# iostr911fa register map
Registers are 16-bit, access not given, no defined reset value unless marked. A register's access mark holds for its fields unless they carry their own. Addresses are absolute; registers are grouped by the start of their names; [hi:lo] are bit positions; {n}, {i} and the like mark numbered series; 'fields as' and 'values as' point back to an identical list.

## GPIO7
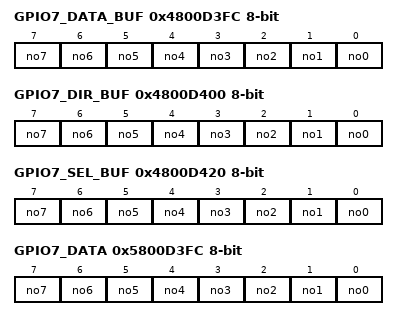
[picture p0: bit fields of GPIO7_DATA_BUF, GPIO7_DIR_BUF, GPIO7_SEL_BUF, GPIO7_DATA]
0x4800D3FC GPIO7_DATA_BUF 8-bit
  [n] no{n} (n=0..7)
0x4800D400 GPIO7_DIR_BUF 8-bit
  [n] no{n} (n=0..7)
0x4800D420 GPIO7_SEL_BUF 8-bit
  [n] no{n} (n=0..7)
0x5800D3FC GPIO7_DATA 8-bit
  [n] no{n} (n=0..7)
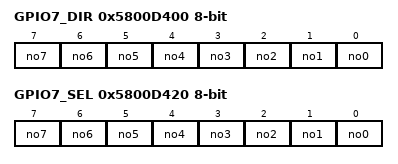
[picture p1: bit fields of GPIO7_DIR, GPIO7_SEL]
0x5800D400 GPIO7_DIR 8-bit
  [n] no{n} (n=0..7)
0x5800D420 GPIO7_SEL 8-bit
  [n] no{n} (n=0..7)

## GPIO8
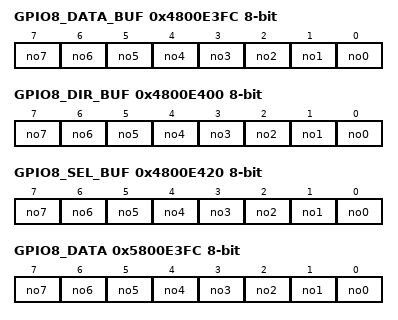
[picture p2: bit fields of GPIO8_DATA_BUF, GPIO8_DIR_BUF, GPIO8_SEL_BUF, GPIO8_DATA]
0x4800E3FC GPIO8_DATA_BUF 8-bit
  [n] no{n} (n=0..7)
0x4800E400 GPIO8_DIR_BUF 8-bit
  [n] no{n} (n=0..7)
0x4800E420 GPIO8_SEL_BUF 8-bit
  [n] no{n} (n=0..7)
0x5800E3FC GPIO8_DATA 8-bit
  [n] no{n} (n=0..7)
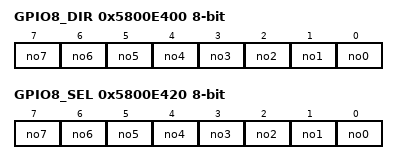
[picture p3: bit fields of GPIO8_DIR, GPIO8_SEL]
0x5800E400 GPIO8_DIR 8-bit
  [n] no{n} (n=0..7)
0x5800E420 GPIO8_SEL 8-bit
  [n] no{n} (n=0..7)

## GPIO9
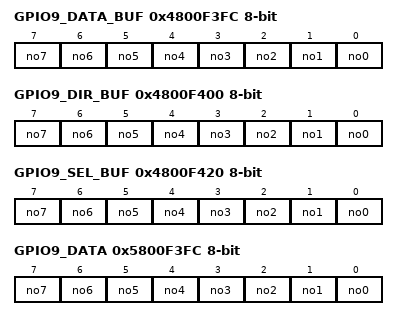
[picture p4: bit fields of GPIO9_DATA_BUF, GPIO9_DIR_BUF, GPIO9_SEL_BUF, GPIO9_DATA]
0x4800F3FC GPIO9_DATA_BUF 8-bit
  [n] no{n} (n=0..7)
0x4800F400 GPIO9_DIR_BUF 8-bit
  [n] no{n} (n=0..7)
0x4800F420 GPIO9_SEL_BUF 8-bit
  [n] no{n} (n=0..7)
0x5800F3FC GPIO9_DATA 8-bit
  [n] no{n} (n=0..7)
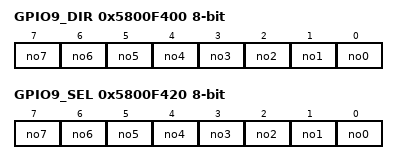
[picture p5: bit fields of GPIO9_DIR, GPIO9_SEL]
0x5800F400 GPIO9_DIR 8-bit
  [n] no{n} (n=0..7)
0x5800F420 GPIO9_SEL 8-bit
  [n] no{n} (n=0..7)

## VIC0
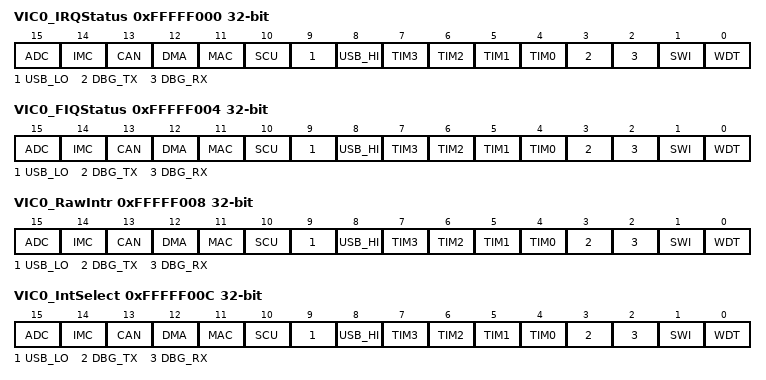
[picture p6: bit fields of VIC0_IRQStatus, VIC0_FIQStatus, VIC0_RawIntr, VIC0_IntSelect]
0xFFFFF000 VIC0_IRQStatus 32-bit
  [15] ADC, [14] IMC, [13] CAN, [12] DMA, [11] MAC, [10] SCU, [9] USB_LO, [8] USB_HI, [n+4] TIM{n} (n=0..3), [3] DBG_TX, [2] DBG_RX, [1] SWI, [0] WDT
0xFFFFF004 VIC0_FIQStatus 32-bit
  fields as VIC0_IRQStatus
0xFFFFF008 VIC0_RawIntr 32-bit
  fields as VIC0_IRQStatus
0xFFFFF00C VIC0_IntSelect 32-bit
  fields as VIC0_IRQStatus
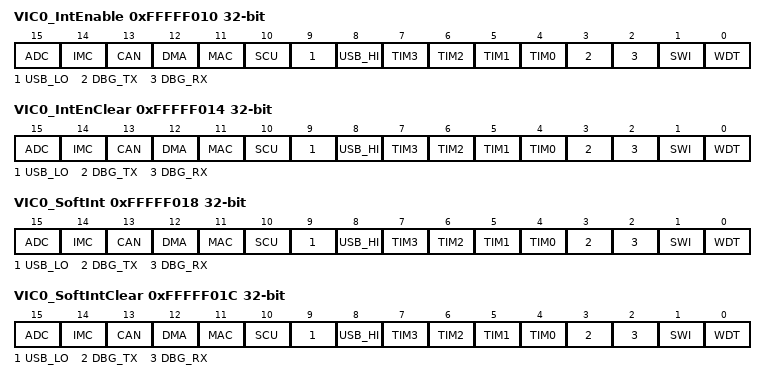
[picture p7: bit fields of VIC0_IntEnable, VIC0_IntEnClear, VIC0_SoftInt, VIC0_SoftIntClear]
0xFFFFF010 VIC0_IntEnable 32-bit
  fields as VIC0_IRQStatus
0xFFFFF014 VIC0_IntEnClear 32-bit
  fields as VIC0_IRQStatus
0xFFFFF018 VIC0_SoftInt 32-bit
  fields as VIC0_IRQStatus
0xFFFFF01C VIC0_SoftIntClear 32-bit
  fields as VIC0_IRQStatus
0xFFFFF020 VIC0_Protection 32-bit
  [0] PROT
0xFFFFF030 VIC0_CurrVectAddr 32-bit
0xFFFFF034 VIC0_DefVectAddr 32-bit
{0xFFFFF100+4i} VIC0_VectAddr{i} 32-bit (i=0..15)
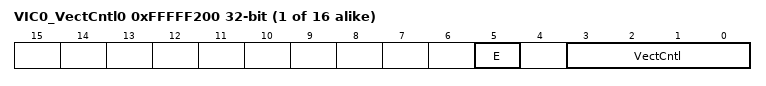
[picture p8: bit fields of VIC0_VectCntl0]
{0xFFFFF200+4i} VIC0_VectCntl{i} 32-bit (i=0..15)
  [5] E, [3:0] VectCntl

## VIC1
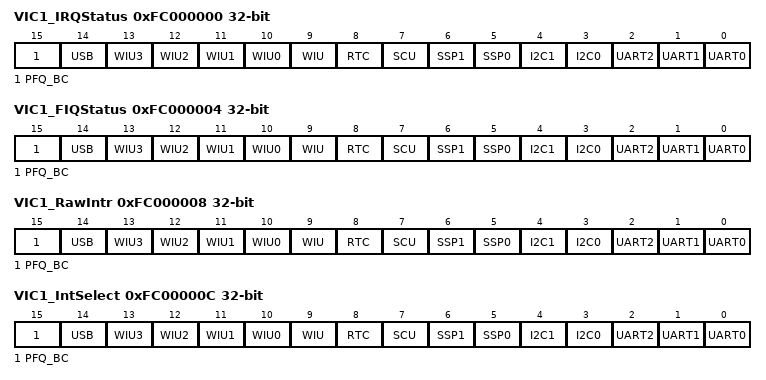
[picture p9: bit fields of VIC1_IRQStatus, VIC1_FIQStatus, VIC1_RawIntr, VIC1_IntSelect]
0xFC000000 VIC1_IRQStatus 32-bit
  [15] PFQ_BC, [14] USB, [n+10] WIU{n} (n=0..3), [9] WIU, [8] RTC, [7] SCU, [6] SSP1, [5] SSP0, [4] I2C1, [3] I2C0, [2] UART2, [1] UART1, [0] UART0
0xFC000004 VIC1_FIQStatus 32-bit
  fields as VIC1_IRQStatus
0xFC000008 VIC1_RawIntr 32-bit
  fields as VIC1_IRQStatus
0xFC00000C VIC1_IntSelect 32-bit
  fields as VIC1_IRQStatus
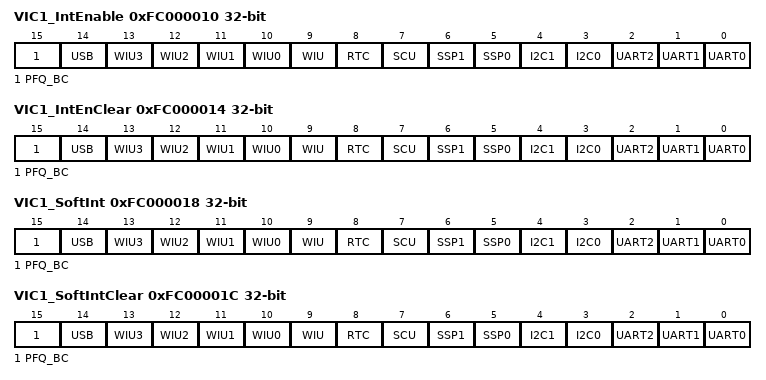
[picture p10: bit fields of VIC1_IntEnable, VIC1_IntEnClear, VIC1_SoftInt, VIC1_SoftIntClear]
0xFC000010 VIC1_IntEnable 32-bit
  fields as VIC1_IRQStatus
0xFC000014 VIC1_IntEnClear 32-bit
  fields as VIC1_IRQStatus
0xFC000018 VIC1_SoftInt 32-bit
  fields as VIC1_IRQStatus
0xFC00001C VIC1_SoftIntClear 32-bit
  fields as VIC1_IRQStatus
0xFC000020 VIC1_Protection 32-bit
  [0] PROT
0xFC000030 VIC1_CurrVectAddr 32-bit
0xFC000034 VIC1_DefVectAddr 32-bit
{0xFC000100+4i} VIC1_VectAddr{i} 32-bit (i=0..15)
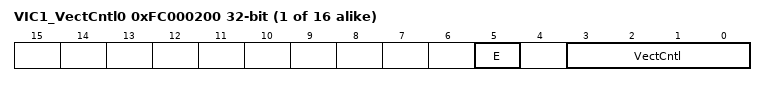
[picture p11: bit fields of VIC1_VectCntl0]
{0xFC000200+4i} VIC1_VectCntl{i} 32-bit (i=0..15)
  [5] E, [3:0] VectCntl

## WIU
0x48001000 WIU_CTRL_BUF 32-bit
  [1] INT_EN
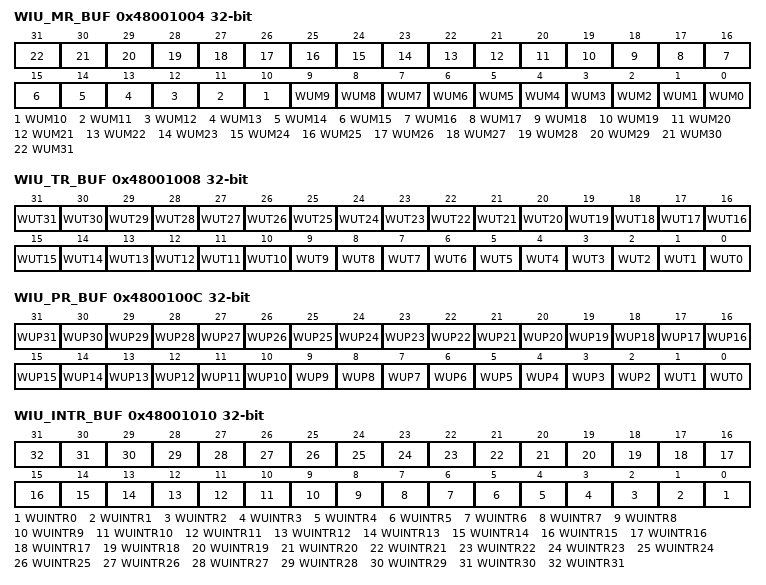
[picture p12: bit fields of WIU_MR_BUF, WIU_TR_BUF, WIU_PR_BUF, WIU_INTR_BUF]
0x48001004 WIU_MR_BUF 32-bit
  [n] WUM{n} (n=0..31)
0x48001008 WIU_TR_BUF 32-bit
  [n] WUT{n} (n=0..31)
0x4800100C WIU_PR_BUF 32-bit
  [n] WUP{n} (n=2..31), [1] WUT1, [0] WUT0
0x48001010 WIU_INTR_BUF 32-bit
  [n] WUINTR{n} (n=0..31)
0x58001000 WIU_CTRL 32-bit
  [1] INT_EN
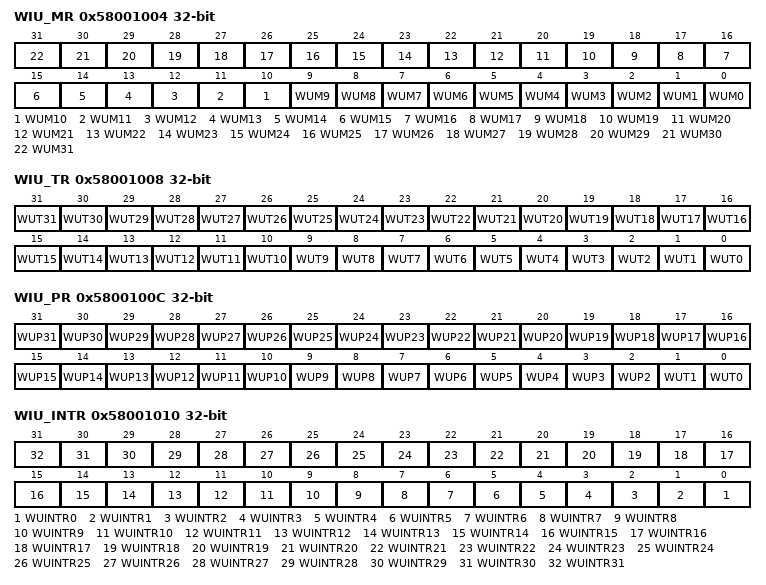
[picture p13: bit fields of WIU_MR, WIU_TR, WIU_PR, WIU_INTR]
0x58001004 WIU_MR 32-bit
  [n] WUM{n} (n=0..31)
0x58001008 WIU_TR 32-bit
  [n] WUT{n} (n=0..31)
0x5800100C WIU_PR 32-bit
  [n] WUP{n} (n=2..31), [1] WUT1, [0] WUT0
0x58001010 WIU_INTR 32-bit
  [n] WUINTR{n} (n=0..31)

## RTC
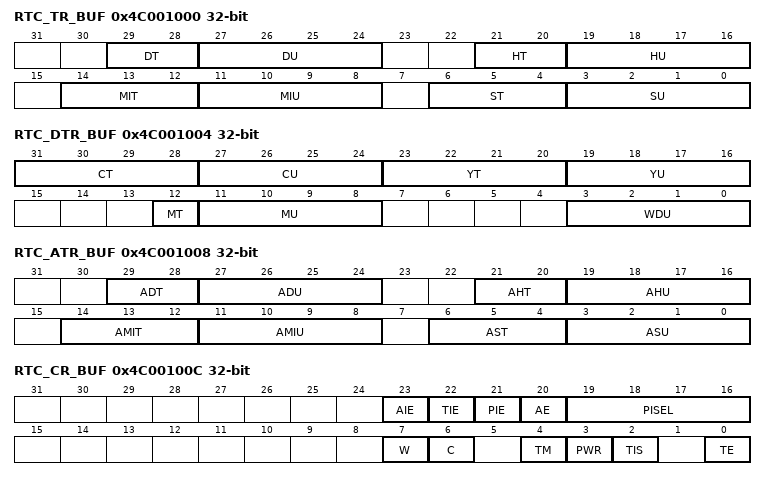
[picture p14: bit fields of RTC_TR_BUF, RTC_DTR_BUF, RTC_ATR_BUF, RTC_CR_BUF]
0x4C001000 RTC_TR_BUF 32-bit
  [29:28] DT, [27:24] DU, [21:20] HT, [19:16] HU, [14:12] MIT, [11:8] MIU, [6:4] ST, [3:0] SU
0x4C001004 RTC_DTR_BUF 32-bit
  [31:28] CT, [27:24] CU, [23:20] YT, [19:16] YU, [12] MT, [11:8] MU, [3:0] WDU
0x4C001008 RTC_ATR_BUF 32-bit
  [29:28] ADT, [27:24] ADU, [21:20] AHT, [19:16] AHU, [14:12] AMIT, [11:8] AMIU, [6:4] AST, [3:0] ASU
0x4C00100C RTC_CR_BUF 32-bit
  [23] AIE, [22] TIE, [21] PIE, [20] AE, [19:16] PISEL, [7] W, [6] C, [4] TM, [3] PWR, [2] TIS, [0] TE
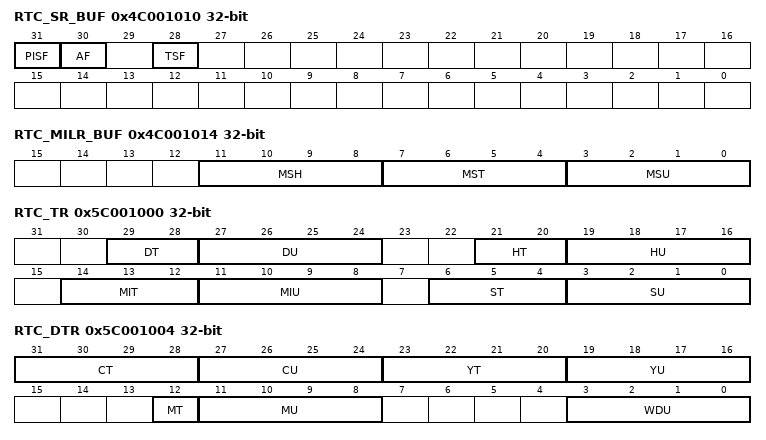
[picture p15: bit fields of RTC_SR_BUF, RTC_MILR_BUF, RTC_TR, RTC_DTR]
0x4C001010 RTC_SR_BUF 32-bit
  [31] PISF, [30] AF, [28] TSF
0x4C001014 RTC_MILR_BUF 32-bit
  [11:8] MSH, [7:4] MST, [3:0] MSU
0x5C001000 RTC_TR 32-bit
  fields as RTC_TR_BUF
0x5C001004 RTC_DTR 32-bit
  fields as RTC_DTR_BUF
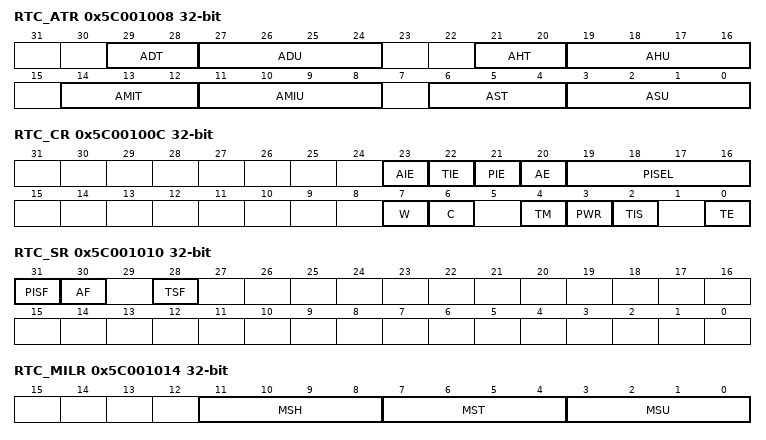
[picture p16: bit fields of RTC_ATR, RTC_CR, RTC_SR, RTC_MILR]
0x5C001008 RTC_ATR 32-bit
  fields as RTC_ATR_BUF
0x5C00100C RTC_CR 32-bit
  fields as RTC_CR_BUF
0x5C001010 RTC_SR 32-bit
  [31] PISF, [30] AF, [28] TSF
0x5C001014 RTC_MILR 32-bit
  [11:8] MSH, [7:4] MST, [3:0] MSU
